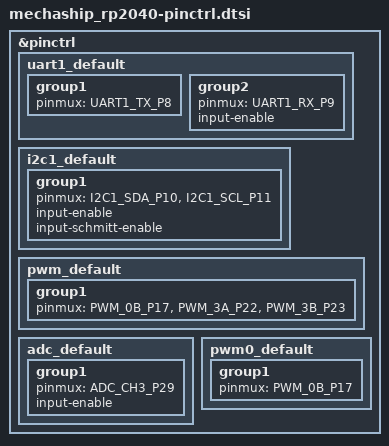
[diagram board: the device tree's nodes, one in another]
/*
 * SPDX-License-Identifier: Apache-2.0
 */

#include <zephyr/dt-bindings/pinctrl/rpi-pico-rp2040-pinctrl.h>

&pinctrl {
	uart1_default: uart1_default {
		group1 {
			pinmux = <UART1_TX_P8>;
		};

		group2 {
			pinmux = <UART1_RX_P9>;
			input-enable;
		};
	};

	i2c1_default: i2c1_default {
		group1 {
			pinmux = <I2C1_SDA_P10>, <I2C1_SCL_P11>;
			input-enable;
			input-schmitt-enable;
		};
	};

	pwm_default: pwm_default {
		group1 {
			pinmux = <PWM_0B_P17>, <PWM_3A_P22>, <PWM_3B_P23>;
		};
	};

	adc_default: adc_default {
		group1 {
			pinmux = <ADC_CH3_P29>;
			input-enable;
		};
	};
	
	pwm0_default: pwm0_default {
		group1 {
			pinmux = <PWM_0B_P17>;
		};
	};
};

